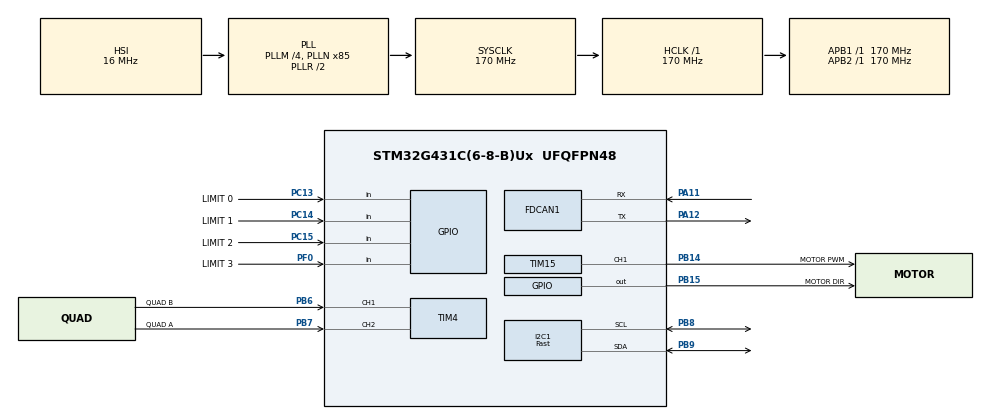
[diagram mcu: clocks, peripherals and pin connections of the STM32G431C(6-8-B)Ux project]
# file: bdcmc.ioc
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Dma.I2C1_RX.0.Direction=DMA_PERIPH_TO_MEMORY
Dma.I2C1_RX.0.EventEnable=DISABLE
Dma.I2C1_RX.0.Instance=DMA1_Channel1
Dma.I2C1_RX.0.MemDataAlignment=DMA_MDATAALIGN_BYTE
Dma.I2C1_RX.0.MemInc=DMA_MINC_ENABLE
Dma.I2C1_RX.0.Mode=DMA_NORMAL
Dma.I2C1_RX.0.PeriphDataAlignment=DMA_PDATAALIGN_BYTE
Dma.I2C1_RX.0.PeriphInc=DMA_PINC_DISABLE
Dma.I2C1_RX.0.Polarity=HAL_DMAMUX_REQ_GEN_RISING
Dma.I2C1_RX.0.Priority=DMA_PRIORITY_MEDIUM
Dma.I2C1_RX.0.RequestNumber=1
Dma.I2C1_RX.0.SignalID=NONE
Dma.I2C1_RX.0.SyncEnable=DISABLE
Dma.I2C1_RX.0.SyncPolarity=HAL_DMAMUX_SYNC_NO_EVENT
Dma.I2C1_RX.0.SyncRequestNumber=1
Dma.I2C1_RX.0.SyncSignalID=NONE
Dma.I2C1_TX.1.Direction=DMA_MEMORY_TO_PERIPH
Dma.I2C1_TX.1.EventEnable=DISABLE
Dma.I2C1_TX.1.Instance=DMA1_Channel2
Dma.I2C1_TX.1.MemDataAlignment=DMA_MDATAALIGN_BYTE
Dma.I2C1_TX.1.MemInc=DMA_MINC_ENABLE
Dma.I2C1_TX.1.Mode=DMA_NORMAL
Dma.I2C1_TX.1.PeriphDataAlignment=DMA_PDATAALIGN_BYTE
Dma.I2C1_TX.1.PeriphInc=DMA_PINC_DISABLE
Dma.I2C1_TX.1.Polarity=HAL_DMAMUX_REQ_GEN_RISING
Dma.I2C1_TX.1.Priority=DMA_PRIORITY_MEDIUM
Dma.I2C1_TX.1.RequestNumber=1
Dma.I2C1_TX.1.SignalID=NONE
Dma.I2C1_TX.1.SyncEnable=DISABLE
Dma.I2C1_TX.1.SyncPolarity=HAL_DMAMUX_SYNC_NO_EVENT
Dma.I2C1_TX.1.SyncRequestNumber=1
Dma.I2C1_TX.1.SyncSignalID=NONE
Dma.Request0=I2C1_RX
Dma.Request1=I2C1_TX
FDCAN1.AutoRetransmission=ENABLE
FDCAN1.CalculateBaudRateNominal=999999
FDCAN1.CalculateTimeBitNominal=1000
FDCAN1.CalculateTimeQuantumNominal=11.764705882352942
FDCAN1.ClockDivider=FDCAN_CLOCK_DIV2
FDCAN1.DataPrescaler=1
FDCAN1.DataSyncJumpWidth=5
FDCAN1.DataTimeSeg1=11
FDCAN1.DataTimeSeg2=5
FDCAN1.ExtFiltersNbr=1
FDCAN1.FrameFormat=FDCAN_FRAME_FD_BRS
FDCAN1.Mode=FDCAN_MODE_NORMAL
FDCAN1.NominalPrescaler=1
FDCAN1.NominalSyncJumpWidth=16
FDCAN1.NominalTimeSeg1=56
FDCAN1.NominalTimeSeg2=28
I2C1.I2C_Speed_Mode=I2C_Fast
I2C1.Timing=0x40621236
Mcu.Family=STM32G4
Mcu.Name=STM32G431C(6-8-B)Ux
Mcu.Package=UFQFPN48
NVIC.DMA1_Channel1_IRQn=true\:0\:0\:false\:false\:true\:false\:true\:true
NVIC.DMA1_Channel2_IRQn=true\:0\:0\:false\:false\:true\:false\:true\:true
NVIC.FDCAN1_IT0_IRQn=true\:0\:0\:false\:false\:true\:true\:true\:true
NVIC.I2C1_ER_IRQn=true\:0\:0\:false\:false\:true\:true\:true\:true
NVIC.I2C1_EV_IRQn=true\:0\:0\:false\:false\:true\:true\:true\:true
NVIC.PriorityGroup=NVIC_PRIORITYGROUP_4
NVIC.TIM1_UP_TIM16_IRQn=true\:1\:0\:true\:false\:true\:true\:true\:true
NVIC.TIM7_IRQn=true\:1\:0\:true\:false\:true\:true\:true\:true
PA11.GPIO_Speed=GPIO_SPEED_FREQ_VERY_HIGH
PA11.Mode=FDCAN_Activate
PA11.Signal=FDCAN1_RX
PA12.GPIO_Speed=GPIO_SPEED_FREQ_VERY_HIGH
PA12.Mode=FDCAN_Activate
PA12.Signal=FDCAN1_TX
PA13.Mode=Serial_Wire
PA13.Signal=SYS_JTMS-SWDIO
PA14.Mode=Serial_Wire
PA14.Signal=SYS_JTCK-SWCLK
PB14.GPIO_Label=MOTOR PWM
PB14.Signal=S_TIM15_CH1
PB15.GPIO_Label=MOTOR DIR
PB15.Signal=GPIO_Output
PB6.GPIO_Label=QUAD B
PB6.Signal=S_TIM4_CH1
PB7.GPIO_Label=QUAD A
PB7.Signal=S_TIM4_CH2
PB8-BOOT0.GPIO_FM8=SYSCFG_FASTMODEPLUS_PB8
PB8-BOOT0.GPIO_Pu=GPIO_NOPULL
PB8-BOOT0.GPIO_Speed=GPIO_SPEED_FREQ_VERY_HIGH
PB8-BOOT0.Mode=I2C
PB8-BOOT0.Signal=I2C1_SCL
PB9.GPIO_FM9=SYSCFG_FASTMODEPLUS_PB9
PB9.GPIO_Pu=GPIO_NOPULL
PB9.GPIO_Speed=GPIO_SPEED_FREQ_VERY_HIGH
PB9.Mode=I2C
PB9.Signal=I2C1_SDA
PC13.GPIO_Label=LIMIT 0
PC13.GPIO_PuPd=GPIO_PULLUP
PC13.Signal=GPIO_Input
PC14-OSC32_IN.GPIO_Label=LIMIT 1
PC14-OSC32_IN.GPIO_PuPd=GPIO_PULLUP
PC14-OSC32_IN.Signal=GPIO_Input
PC15-OSC32_OUT.GPIO_Label=LIMIT 2
PC15-OSC32_OUT.GPIO_PuPd=GPIO_PULLUP
PC15-OSC32_OUT.Signal=GPIO_Input
PF0-OSC_IN.GPIO_Label=LIMIT 3
PF0-OSC_IN.GPIO_PuPd=GPIO_PULLUP
PF0-OSC_IN.Signal=GPIO_Input
ProjectManager.HeapSize=0x200
ProjectManager.StackSize=0x400
ProjectManager.TargetToolchain=STM32CubeIDE
RCC.ADC12Freq_Value=170000000
RCC.AHBFreq_Value=170000000
RCC.APB1Freq_Value=170000000
RCC.APB1TimFreq_Value=170000000
RCC.APB2Freq_Value=170000000
RCC.APB2TimFreq_Value=170000000
RCC.CortexFreq_Value=170000000
RCC.EXTERNAL_CLOCK_VALUE=12288000
RCC.HCLKFreq_Value=170000000
RCC.HSE_VALUE=8000000
RCC.HSI48_VALUE=48000000
RCC.HSI_VALUE=16000000
RCC.LSE_VALUE=32768
RCC.PLLM=RCC_PLLM_DIV4
RCC.PLLN=85
RCC.SYSCLKFreq_VALUE=170000000
RCC.SYSCLKSource=RCC_SYSCLKSOURCE_PLLCLK
RCC.USBFreq_Value=170000000
RCC.VCOOutputFreq_Value=340000000
SH.S_TIM15_CH1.0=TIM15_CH1,PWM Generation1 CH1
SH.S_TIM4_CH1.0=TIM4_CH1,Encoder_Interface
SH.S_TIM4_CH2.0=TIM4_CH2,Encoder_Interface
TIM15.Channel-PWM\ Generation1\ CH1=TIM_CHANNEL_1
TIM15.PeriodNoDither=99
TIM15.Prescaler=78
TIM16.PeriodNoDither=54580
TIM16.Prescaler=621
TIM2.AutoReloadPreload=TIM_AUTORELOAD_PRELOAD_ENABLE
TIM2.PeriodNoDither=4294967295
TIM2.Prescaler=169
TIM4.EncoderMode=TIM_ENCODERMODE_TI12
TIM7.AutoReloadPreload=TIM_AUTORELOAD_PRELOAD_ENABLE
TIM7.PeriodNoDither=49999
TIM7.Prescaler=169
VP_SYS_VS_DBSignals.Mode=DisableDeadBatterySignals
VP_TIM16_VS_ClockSourceINT.Mode=Enable_Timer
VP_TIM2_VS_ClockSourceINT.Mode=Internal
VP_TIM7_VS_ClockSourceINT.Mode=Enable_Timer
board=custom

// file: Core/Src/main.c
/* USER CODE BEGIN Header */
/**
  ******************************************************************************
  * @file           : main.c
  * @brief          : Main program body
  ******************************************************************************
  * @attention
  *
  * Copyright (c) 2025 STMicroelectronics.
  * All rights reserved.
  *
  * This software is licensed under terms that can be found in the LICENSE file
  * in the root directory of this software component.
  * If no LICENSE file comes with this software, it is provided AS-IS.
  *
  ******************************************************************************
  */
/* USER CODE END Header */
#include "main.h"

FDCAN_HandleTypeDef hfdcan1;

I2C_HandleTypeDef hi2c1;
DMA_HandleTypeDef hdma_i2c1_rx;
DMA_HandleTypeDef hdma_i2c1_tx;

TIM_HandleTypeDef htim2;
TIM_HandleTypeDef htim4;
TIM_HandleTypeDef htim7;
TIM_HandleTypeDef htim15;
TIM_HandleTypeDef htim16;

void SystemClock_Config(void);
static void MX_GPIO_Init(void);
static void MX_DMA_Init(void);
static void MX_FDCAN1_Init(void);
static void MX_I2C1_Init(void);
static void MX_TIM15_Init(void);
static void MX_TIM7_Init(void);
static void MX_TIM16_Init(void);
static void MX_TIM2_Init(void);
static void MX_TIM4_Init(void);

int main(void)
{

  /* MCU Configuration--------------------------------------------------------*/

  /* Reset of all peripherals, Initializes the Flash interface and the Systick. */
  HAL_Init();

  /* Configure the system clock */
  SystemClock_Config();

  /* Initialize all configured peripherals */
  MX_GPIO_Init();
  MX_DMA_Init();
  MX_FDCAN1_Init();
  MX_I2C1_Init();
  MX_TIM15_Init();
  MX_TIM7_Init();
  MX_TIM16_Init();
  MX_TIM2_Init();
  MX_TIM4_Init();
  /* USER CODE BEGIN 2 */
  HAL_PostInit();
  /* USER CODE END 2 */

  /* Infinite loop */
  while (1)
  {

  }
}

void SystemClock_Config(void)
{
  RCC_OscInitTypeDef RCC_OscInitStruct = {0};
  RCC_ClkInitTypeDef RCC_ClkInitStruct = {0};

  /** Configure the main internal regulator output voltage
  */
  HAL_PWREx_ControlVoltageScaling(PWR_REGULATOR_VOLTAGE_SCALE1_BOOST);

  /** Initializes the RCC Oscillators according to the specified parameters
  * in the RCC_OscInitTypeDef structure.
  */
  RCC_OscInitStruct.OscillatorType = RCC_OSCILLATORTYPE_HSI;
  RCC_OscInitStruct.HSIState = RCC_HSI_ON;
  RCC_OscInitStruct.HSICalibrationValue = RCC_HSICALIBRATION_DEFAULT;
  RCC_OscInitStruct.PLL.PLLState = RCC_PLL_ON;
  RCC_OscInitStruct.PLL.PLLSource = RCC_PLLSOURCE_HSI;
  RCC_OscInitStruct.PLL.PLLM = RCC_PLLM_DIV4;
  RCC_OscInitStruct.PLL.PLLN = 85;
  RCC_OscInitStruct.PLL.PLLP = RCC_PLLP_DIV2;
  RCC_OscInitStruct.PLL.PLLQ = RCC_PLLQ_DIV2;
  RCC_OscInitStruct.PLL.PLLR = RCC_PLLR_DIV2;
  if (HAL_RCC_OscConfig(&RCC_OscInitStruct) != HAL_OK)
  {
    Error_Handler();
  }

  /** Initializes the CPU, AHB and APB buses clocks
  */
  RCC_ClkInitStruct.ClockType = RCC_CLOCKTYPE_HCLK|RCC_CLOCKTYPE_SYSCLK
                              |RCC_CLOCKTYPE_PCLK1|RCC_CLOCKTYPE_PCLK2;
  RCC_ClkInitStruct.SYSCLKSource = RCC_SYSCLKSOURCE_PLLCLK;
  RCC_ClkInitStruct.AHBCLKDivider = RCC_SYSCLK_DIV1;
  RCC_ClkInitStruct.APB1CLKDivider = RCC_HCLK_DIV1;
  RCC_ClkInitStruct.APB2CLKDivider = RCC_HCLK_DIV1;

  if (HAL_RCC_ClockConfig(&RCC_ClkInitStruct, FLASH_LATENCY_4) != HAL_OK)
  {
    Error_Handler();
  }
}

static void MX_FDCAN1_Init(void)
{

  hfdcan1.Instance = FDCAN1;
  hfdcan1.Init.ClockDivider = FDCAN_CLOCK_DIV2;
  hfdcan1.Init.FrameFormat = FDCAN_FRAME_FD_BRS;
  hfdcan1.Init.Mode = FDCAN_MODE_NORMAL;
  hfdcan1.Init.AutoRetransmission = ENABLE;
  hfdcan1.Init.TransmitPause = DISABLE;
  hfdcan1.Init.ProtocolException = DISABLE;
  hfdcan1.Init.NominalPrescaler = 1;
  hfdcan1.Init.NominalSyncJumpWidth = 16;
  hfdcan1.Init.NominalTimeSeg1 = 56;
  hfdcan1.Init.NominalTimeSeg2 = 28;
  hfdcan1.Init.DataPrescaler = 1;
  hfdcan1.Init.DataSyncJumpWidth = 5;
  hfdcan1.Init.DataTimeSeg1 = 11;
  hfdcan1.Init.DataTimeSeg2 = 5;
  hfdcan1.Init.StdFiltersNbr = 0;
  hfdcan1.Init.ExtFiltersNbr = 1;
  hfdcan1.Init.TxFifoQueueMode = FDCAN_TX_FIFO_OPERATION;
  if (HAL_FDCAN_Init(&hfdcan1) != HAL_OK)
  {
    Error_Handler();
  }

}

static void MX_I2C1_Init(void)
{

  hi2c1.Instance = I2C1;
  hi2c1.Init.Timing = 0x40621236;
  hi2c1.Init.OwnAddress1 = 0;
  hi2c1.Init.AddressingMode = I2C_ADDRESSINGMODE_7BIT;
  hi2c1.Init.DualAddressMode = I2C_DUALADDRESS_DISABLE;
  hi2c1.Init.OwnAddress2 = 0;
  hi2c1.Init.OwnAddress2Masks = I2C_OA2_NOMASK;
  hi2c1.Init.GeneralCallMode = I2C_GENERALCALL_DISABLE;
  hi2c1.Init.NoStretchMode = I2C_NOSTRETCH_DISABLE;
  if (HAL_I2C_Init(&hi2c1) != HAL_OK)
  {
    Error_Handler();
  }

  /** Configure Analogue filter
  */
  if (HAL_I2CEx_ConfigAnalogFilter(&hi2c1, I2C_ANALOGFILTER_ENABLE) != HAL_OK)
  {
    Error_Handler();
  }

  /** Configure Digital filter
  */
  if (HAL_I2CEx_ConfigDigitalFilter(&hi2c1, 0) != HAL_OK)
  {
    Error_Handler();
  }

}

static void MX_TIM2_Init(void)
{

  TIM_ClockConfigTypeDef sClockSourceConfig = {0};
  TIM_MasterConfigTypeDef sMasterConfig = {0};

  htim2.Instance = TIM2;
  htim2.Init.Prescaler = 169;
  htim2.Init.CounterMode = TIM_COUNTERMODE_UP;
  htim2.Init.Period = 4294967295;
  htim2.Init.ClockDivision = TIM_CLOCKDIVISION_DIV1;
  htim2.Init.AutoReloadPreload = TIM_AUTORELOAD_PRELOAD_ENABLE;
  if (HAL_TIM_Base_Init(&htim2) != HAL_OK)
  {
    Error_Handler();
  }
  sClockSourceConfig.ClockSource = TIM_CLOCKSOURCE_INTERNAL;
  if (HAL_TIM_ConfigClockSource(&htim2, &sClockSourceConfig) != HAL_OK)
  {
    Error_Handler();
  }
  sMasterConfig.MasterOutputTrigger = TIM_TRGO_RESET;
  sMasterConfig.MasterSlaveMode = TIM_MASTERSLAVEMODE_DISABLE;
  if (HAL_TIMEx_MasterConfigSynchronization(&htim2, &sMasterConfig) != HAL_OK)
  {
    Error_Handler();
  }

}

static void MX_TIM4_Init(void)
{

  TIM_Encoder_InitTypeDef sConfig = {0};
  TIM_MasterConfigTypeDef sMasterConfig = {0};

  htim4.Instance = TIM4;
  htim4.Init.Prescaler = 0;
  htim4.Init.CounterMode = TIM_COUNTERMODE_UP;
  htim4.Init.Period = 65535;
  htim4.Init.ClockDivision = TIM_CLOCKDIVISION_DIV1;
  htim4.Init.AutoReloadPreload = TIM_AUTORELOAD_PRELOAD_DISABLE;
  sConfig.EncoderMode = TIM_ENCODERMODE_TI12;
  sConfig.IC1Polarity = TIM_ICPOLARITY_RISING;
  sConfig.IC1Selection = TIM_ICSELECTION_DIRECTTI;
  sConfig.IC1Prescaler = TIM_ICPSC_DIV1;
  sConfig.IC1Filter = 0;
  sConfig.IC2Polarity = TIM_ICPOLARITY_RISING;
  sConfig.IC2Selection = TIM_ICSELECTION_DIRECTTI;
  sConfig.IC2Prescaler = TIM_ICPSC_DIV1;
  sConfig.IC2Filter = 0;
  if (HAL_TIM_Encoder_Init(&htim4, &sConfig) != HAL_OK)
  {
    Error_Handler();
  }
  sMasterConfig.MasterOutputTrigger = TIM_TRGO_RESET;
  sMasterConfig.MasterSlaveMode = TIM_MASTERSLAVEMODE_DISABLE;
  if (HAL_TIMEx_MasterConfigSynchronization(&htim4, &sMasterConfig) != HAL_OK)
  {
    Error_Handler();
  }

}

static void MX_TIM7_Init(void)
{

  TIM_MasterConfigTypeDef sMasterConfig = {0};

  htim7.Instance = TIM7;
  htim7.Init.Prescaler = 169;
  htim7.Init.CounterMode = TIM_COUNTERMODE_UP;
  htim7.Init.Period = 49999;
  htim7.Init.AutoReloadPreload = TIM_AUTORELOAD_PRELOAD_ENABLE;
  if (HAL_TIM_Base_Init(&htim7) != HAL_OK)
  {
    Error_Handler();
  }
  sMasterConfig.MasterOutputTrigger = TIM_TRGO_RESET;
  sMasterConfig.MasterSlaveMode = TIM_MASTERSLAVEMODE_DISABLE;
  if (HAL_TIMEx_MasterConfigSynchronization(&htim7, &sMasterConfig) != HAL_OK)
  {
    Error_Handler();
  }

}

static void MX_TIM15_Init(void)
{

  TIM_MasterConfigTypeDef sMasterConfig = {0};
  TIM_OC_InitTypeDef sConfigOC = {0};
  TIM_BreakDeadTimeConfigTypeDef sBreakDeadTimeConfig = {0};

  htim15.Instance = TIM15;
  htim15.Init.Prescaler = 78;
  htim15.Init.CounterMode = TIM_COUNTERMODE_UP;
  htim15.Init.Period = 99;
  htim15.Init.ClockDivision = TIM_CLOCKDIVISION_DIV1;
  htim15.Init.RepetitionCounter = 0;
  htim15.Init.AutoReloadPreload = TIM_AUTORELOAD_PRELOAD_DISABLE;
  if (HAL_TIM_PWM_Init(&htim15) != HAL_OK)
  {
    Error_Handler();
  }
  sMasterConfig.MasterOutputTrigger = TIM_TRGO_RESET;
  sMasterConfig.MasterSlaveMode = TIM_MASTERSLAVEMODE_DISABLE;
  if (HAL_TIMEx_MasterConfigSynchronization(&htim15, &sMasterConfig) != HAL_OK)
  {
    Error_Handler();
  }
  sConfigOC.OCMode = TIM_OCMODE_PWM1;
  sConfigOC.Pulse = 0;
  sConfigOC.OCPolarity = TIM_OCPOLARITY_HIGH;
  sConfigOC.OCNPolarity = TIM_OCNPOLARITY_HIGH;
  sConfigOC.OCFastMode = TIM_OCFAST_DISABLE;
  sConfigOC.OCIdleState = TIM_OCIDLESTATE_RESET;
  sConfigOC.OCNIdleState = TIM_OCNIDLESTATE_RESET;
  if (HAL_TIM_PWM_ConfigChannel(&htim15, &sConfigOC, TIM_CHANNEL_1) != HAL_OK)
  {
    Error_Handler();
  }
  sBreakDeadTimeConfig.OffStateRunMode = TIM_OSSR_DISABLE;
  sBreakDeadTimeConfig.OffStateIDLEMode = TIM_OSSI_DISABLE;
  sBreakDeadTimeConfig.LockLevel = TIM_LOCKLEVEL_OFF;
  sBreakDeadTimeConfig.DeadTime = 0;
  sBreakDeadTimeConfig.BreakState = TIM_BREAK_DISABLE;
  sBreakDeadTimeConfig.BreakPolarity = TIM_BREAKPOLARITY_HIGH;
  sBreakDeadTimeConfig.BreakFilter = 0;
  sBreakDeadTimeConfig.AutomaticOutput = TIM_AUTOMATICOUTPUT_DISABLE;
  if (HAL_TIMEx_ConfigBreakDeadTime(&htim15, &sBreakDeadTimeConfig) != HAL_OK)
  {
    Error_Handler();
  }
  HAL_TIM_MspPostInit(&htim15);

}

static void MX_TIM16_Init(void)
{

  htim16.Instance = TIM16;
  htim16.Init.Prescaler = 621;
  htim16.Init.CounterMode = TIM_COUNTERMODE_UP;
  htim16.Init.Period = 54580;
  htim16.Init.ClockDivision = TIM_CLOCKDIVISION_DIV1;
  htim16.Init.RepetitionCounter = 0;
  htim16.Init.AutoReloadPreload = TIM_AUTORELOAD_PRELOAD_DISABLE;
  if (HAL_TIM_Base_Init(&htim16) != HAL_OK)
  {
    Error_Handler();
  }

}

static void MX_DMA_Init(void)
{

  /* DMA controller clock enable */
  __HAL_RCC_DMAMUX1_CLK_ENABLE();
  __HAL_RCC_DMA1_CLK_ENABLE();

  /* DMA interrupt init */
  /* DMA1_Channel1_IRQn interrupt configuration */
  HAL_NVIC_SetPriority(DMA1_Channel1_IRQn, 0, 0);
  HAL_NVIC_EnableIRQ(DMA1_Channel1_IRQn);
  /* DMA1_Channel2_IRQn interrupt configuration */
  HAL_NVIC_SetPriority(DMA1_Channel2_IRQn, 0, 0);
  HAL_NVIC_EnableIRQ(DMA1_Channel2_IRQn);

}

static void MX_GPIO_Init(void)
{
  GPIO_InitTypeDef GPIO_InitStruct = {0};

  /* GPIO Ports Clock Enable */
  __HAL_RCC_GPIOC_CLK_ENABLE();
  __HAL_RCC_GPIOF_CLK_ENABLE();
  __HAL_RCC_GPIOB_CLK_ENABLE();
  __HAL_RCC_GPIOA_CLK_ENABLE();

  /*Configure GPIO pin Output Level */
  HAL_GPIO_WritePin(MOTOR_DIR_GPIO_Port, MOTOR_DIR_Pin, GPIO_PIN_RESET);

  /*Configure GPIO pins : LIMIT_0_Pin LIMIT_1_Pin LIMIT_2_Pin */
  GPIO_InitStruct.Pin = LIMIT_0_Pin|LIMIT_1_Pin|LIMIT_2_Pin;
  GPIO_InitStruct.Mode = GPIO_MODE_INPUT;
  GPIO_InitStruct.Pull = GPIO_PULLUP;
  HAL_GPIO_Init(GPIOC, &GPIO_InitStruct);

  /*Configure GPIO pin : LIMIT_3_Pin */
  GPIO_InitStruct.Pin = LIMIT_3_Pin;
  GPIO_InitStruct.Mode = GPIO_MODE_INPUT;
  GPIO_InitStruct.Pull = GPIO_PULLUP;
  HAL_GPIO_Init(LIMIT_3_GPIO_Port, &GPIO_InitStruct);

  /*Configure GPIO pin : MOTOR_DIR_Pin */
  GPIO_InitStruct.Pin = MOTOR_DIR_Pin;
  GPIO_InitStruct.Mode = GPIO_MODE_OUTPUT_PP;
  GPIO_InitStruct.Pull = GPIO_NOPULL;
  GPIO_InitStruct.Speed = GPIO_SPEED_FREQ_LOW;
  HAL_GPIO_Init(MOTOR_DIR_GPIO_Port, &GPIO_InitStruct);

}

void Error_Handler(void)
{
  __disable_irq();
  while (1)
  {
  }
}
